AUTOSAR XML (schema 00046)
package /Runnable_Lab
  sender receiver interface Result_IN
    data OUT: type=uint32
  sender receiver interface Input_IN
    data Var1: type=uint16
    data Var2: type=uint16
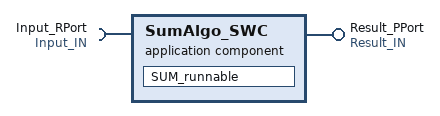
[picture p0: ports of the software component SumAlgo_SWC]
  application sw component type SumAlgo_SWC
    provide port Result_PPort: provided-interface=Result_IN
    require port Input_RPort: required-interface=Input_IN
    behavior Sw1_SUM
      runnable SUM_runnable: symbol=SUM
        data-read-access:
          access Val1_Data: accessed-variable=Input_RPort.Var1
          access Val2_Data: accessed-variable=Input_RPort.Var2
        data-write-access:
          access Out_data: accessed-variable=Result_PPort.OUT
